VERSION ""

NS_ :

BS_:

BU_:

BO_ 96 SourId: 2 Vector__XXX
 SG_ AdcSourCovVal : 0|16@1+ (1,0) [0|0] "" Vector__XXX

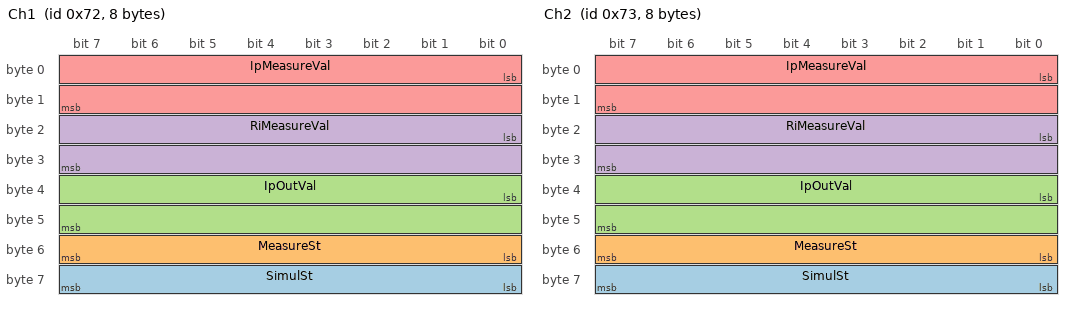
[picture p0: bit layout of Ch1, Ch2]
BO_ 114 Ch1: 8 Vector__XXX
 SG_ SimulSt : 56|8@1+ (1,0) [0|0] "" Vector__XXX
 SG_ MeasureSt : 48|8@1+ (1,0) [0|0] "" Vector__XXX
 SG_ IpOutVal : 32|16@1- (1,0) [0|0] "" Vector__XXX
 SG_ RiMeasureVal : 16|16@1+ (1,0) [0|0] "" Vector__XXX
 SG_ IpMeasureVal : 0|16@1- (1,0) [0|0] "" Vector__XXX

BO_ 115 Ch2: 8 Vector__XXX
 SG_ SimulSt : 56|8@1+ (1,0) [0|0] "" Vector__XXX
 SG_ MeasureSt : 48|8@1+ (1,0) [0|0] "" Vector__XXX
 SG_ IpOutVal : 32|16@1- (1,0) [0|0] "" Vector__XXX
 SG_ RiMeasureVal : 16|16@1+ (1,0) [0|0] "" Vector__XXX
 SG_ IpMeasureVal : 0|16@1- (1,0) [0|0] "" Vector__XXX

BA_DEF_ SG_  "GenSigSendType" ENUM  "Cyclic","OnWrite","OnWriteWithRepetition","OnChange","OnChangeWithRepetition","IfActive","IfActiveWithRepetition","NoSigSendType";
BA_DEF_ BO_  "GenMsgSendType" ENUM  "Cyclic","not_used","not_used","not_used","not_used","Cyclic","not_used","IfActive","NoMsgSendType";
BA_DEF_  "DBName" STRING ;
BA_DEF_  "BusType" STRING ;
BA_DEF_DEF_  "GenSigSendType" "Cyclic";
BA_DEF_DEF_  "GenMsgSendType" "NoMsgSendType";
BA_DEF_DEF_  "DBName" "";
BA_DEF_DEF_  "BusType" "CAN";
BA_ "DBName" "CRT";
